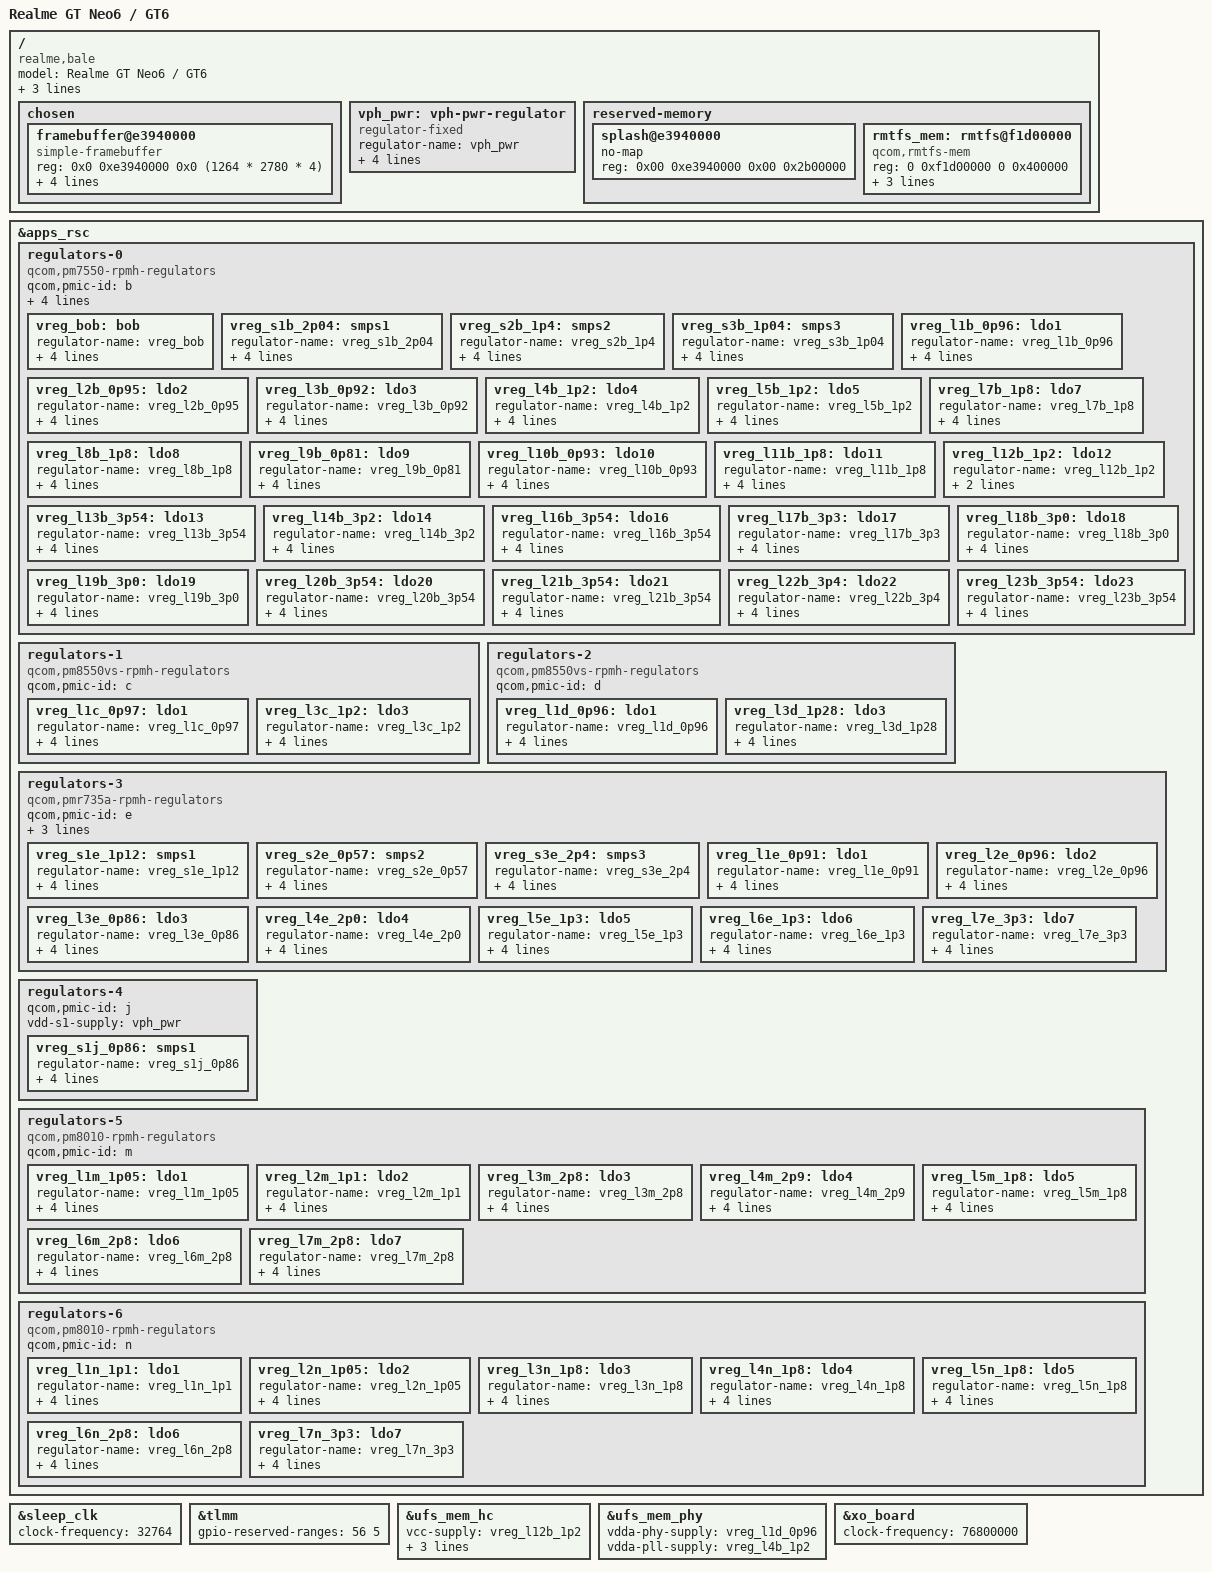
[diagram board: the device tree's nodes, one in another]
// SPDX-License-Identifier: BSD-3-Clause
/*
 * Copyright (c) 2025, Alexandr Zubtsov <internal.hellhound@mainlining.org>
 */

/dts-v1/;

#include <dt-bindings/regulator/qcom,rpmh-regulator.h>
#include "palawan.dtsi"
#include "pm8010.dtsi"
#include "pm7550.dtsi" /* PMXR2230 */
#include "pm7550ba.dtsi"
#define PMK8550VE_SID 3
#include "pm8550ve.dtsi"
#include "pm8550vs.dtsi"
#include "pmk8550.dtsi"
#include "pmr735a.dtsi"

/delete-node/ &rmtfs_mem;

/ {
	model = "Realme GT Neo6 / GT6";
	compatible = "realme,bale", "qcom,palawan";
	chassis-type = "handset";
	qcom,msm-id = <0x282 0x10000 0x266 0x10000>;
	qcom,board-id = <0x08 0x00>;

	chosen {
		#address-cells = <2>;
		#size-cells = <2>;
		ranges;
		framebuffer@e3940000 {
			compatible = "simple-framebuffer";
			reg = <0x0 0xe3940000 0x0 (1264 * 2780 * 4)>;
			width = <1264>;
			height = <2780>;
			stride = <(1264 * 4)>;
			format = "a8r8g8b8";
		};
	};

	vph_pwr: vph-pwr-regulator {
		compatible = "regulator-fixed";

		regulator-name = "vph_pwr";
		regulator-min-microvolt = <3700000>;
		regulator-max-microvolt = <3700000>;

		regulator-always-on;
		regulator-boot-on;
	};

	reserved-memory {
		splash@e3940000 {
			no-map;
			reg = <0x00 0xe3940000 0x00 0x2b00000>;
		};

		rmtfs_mem: rmtfs@f1d00000 {
			compatible = "qcom,rmtfs-mem";
			reg = <0 0xf1d00000 0 0x400000>;
			no-map;

			qcom,client-id = <1>;
			qcom,vmid = <QCOM_SCM_VMID_MSS_MSA>;
		};
	};
};

&apps_rsc {

	regulators-0 {
		compatible = "qcom,pm7550-rpmh-regulators";
		qcom,pmic-id = "b";

		vdd-bob-supply = <&vph_pwr>;
		vdd-s1-supply = <&vph_pwr>;
		vdd-s2-supply = <&vph_pwr>;
		vdd-s3-supply = <&vph_pwr>;

		vreg_bob: bob {
			regulator-name = "vreg_bob";
			regulator-min-microvolt = <3008000>;
			regulator-max-microvolt = <3960000>;
			regulator-initial-mode = <RPMH_REGULATOR_MODE_HPM>;
		};

		vreg_s1b_2p04: smps1 {
			regulator-name = "vreg_s1b_2p04";
			regulator-min-microvolt = <1856000>;
			regulator-max-microvolt = <2040000>;
			regulator-initial-mode = <RPMH_REGULATOR_MODE_HPM>;
		};

		vreg_s2b_1p4: smps2 {
			regulator-name = "vreg_s2b_1p4";
			regulator-min-microvolt = <1256000>;
			regulator-max-microvolt = <1408000>;
			regulator-initial-mode = <RPMH_REGULATOR_MODE_HPM>;
		};

		vreg_s3b_1p04: smps3 {
			regulator-name = "vreg_s3b_1p04";
			regulator-min-microvolt = <968000>;
			regulator-max-microvolt = <1040000>;
			regulator-initial-mode = <RPMH_REGULATOR_MODE_HPM>;
		};

		vreg_l1b_0p96: ldo1 {
			regulator-name = "vreg_l1b_0p96";
			regulator-min-microvolt = <880000>;
			regulator-max-microvolt = <960000>;
			regulator-initial-mode = <RPMH_REGULATOR_MODE_HPM>;
		};

		vreg_l2b_0p95: ldo2 {
			regulator-name = "vreg_l2b_0p95";
			regulator-min-microvolt = <880000>;
			regulator-max-microvolt = <952000>;
			regulator-initial-mode = <RPMH_REGULATOR_MODE_HPM>;
		};

		vreg_l3b_0p92: ldo3 {
			regulator-name = "vreg_l3b_0p92";
			regulator-min-microvolt = <880000>;
			regulator-max-microvolt = <920000>;
			regulator-initial-mode = <RPMH_REGULATOR_MODE_HPM>;
		};

		vreg_l4b_1p2: ldo4 {
			regulator-name = "vreg_l4b_1p2";
			regulator-min-microvolt = <1200000>;
			regulator-max-microvolt = <1200000>;
			regulator-initial-mode = <RPMH_REGULATOR_MODE_HPM>;
		};

		vreg_l5b_1p2: ldo5 {
			regulator-name = "vreg_l5b_1p2";
			regulator-min-microvolt = <1200000>;
			regulator-max-microvolt = <1200000>;
			regulator-initial-mode = <RPMH_REGULATOR_MODE_HPM>;
		};

		vreg_l7b_1p8: ldo7 {
			regulator-name = "vreg_l7b_1p8";
			regulator-min-microvolt = <1800000>;
			regulator-max-microvolt = <1800000>;
			regulator-initial-mode = <RPMH_REGULATOR_MODE_HPM>;
		};

		vreg_l8b_1p8: ldo8 {
			regulator-name = "vreg_l8b_1p8";
			regulator-min-microvolt = <1800000>;
			regulator-max-microvolt = <1800000>;
			regulator-initial-mode = <RPMH_REGULATOR_MODE_HPM>;
		};

		vreg_l9b_0p81: ldo9 {
			regulator-name = "vreg_l9b_0p81";
			regulator-min-microvolt = <756000>;
			regulator-max-microvolt = <816000>;
			regulator-initial-mode = <RPMH_REGULATOR_MODE_HPM>;
		};

		vreg_l10b_0p93: ldo10 {
			regulator-name = "vreg_l10b_0p93";
			regulator-min-microvolt = <868000>;
			regulator-max-microvolt = <932000>;
			regulator-initial-mode = <RPMH_REGULATOR_MODE_HPM>;
		};

		vreg_l11b_1p8: ldo11 {
			regulator-name = "vreg_l11b_1p8";
			regulator-min-microvolt = <1800000>;
			regulator-max-microvolt = <1800000>;
			regulator-initial-mode = <RPMH_REGULATOR_MODE_HPM>;
		};

		vreg_l12b_1p2: ldo12 {
			regulator-name = "vreg_l12b_1p2";
			regulator-initial-mode = <RPMH_REGULATOR_MODE_HPM>;
		};

		vreg_l13b_3p54: ldo13 {
			regulator-name = "vreg_l13b_3p54";
			regulator-min-microvolt = <1504000>;
			regulator-max-microvolt = <3544000>;
			regulator-initial-mode = <RPMH_REGULATOR_MODE_HPM>;
		};

		vreg_l14b_3p2: ldo14 {
			regulator-name = "vreg_l14b_3p2";
			regulator-min-microvolt = <3008000>;
			regulator-max-microvolt = <3200000>;
			regulator-initial-mode = <RPMH_REGULATOR_MODE_HPM>;
		};

		vreg_l16b_3p54: ldo16 {
			regulator-name = "vreg_l16b_3p54";
			regulator-min-microvolt = <2900000>;
			regulator-max-microvolt = <3544000>;
			regulator-initial-mode = <RPMH_REGULATOR_MODE_HPM>;
		};

		vreg_l17b_3p3: ldo17 {
			regulator-name = "vreg_l17b_3p3";
			regulator-min-microvolt = <2700000>;
			regulator-max-microvolt = <3300000>;
			regulator-initial-mode = <RPMH_REGULATOR_MODE_HPM>;
		};

		vreg_l18b_3p0: ldo18 {
			regulator-name = "vreg_l18b_3p0";
			regulator-min-microvolt = <2000000>;
			regulator-max-microvolt = <3000000>;
			regulator-initial-mode = <RPMH_REGULATOR_MODE_HPM>;
		};

		vreg_l19b_3p0: ldo19 {
			regulator-name = "vreg_l19b_3p0";
			regulator-min-microvolt = <2600000>;
			regulator-max-microvolt = <3000000>;
			regulator-initial-mode = <RPMH_REGULATOR_MODE_HPM>;
		};

		vreg_l20b_3p54: ldo20 {
			regulator-name = "vreg_l20b_3p54";
			regulator-min-microvolt = <1620000>;
			regulator-max-microvolt = <3544000>;
			regulator-initial-mode = <RPMH_REGULATOR_MODE_HPM>;
		};

		vreg_l21b_3p54: ldo21 {
			regulator-name = "vreg_l21b_3p54";
			regulator-min-microvolt = <1620000>;
			regulator-max-microvolt = <3544000>;
			regulator-initial-mode = <RPMH_REGULATOR_MODE_HPM>;
		};

		vreg_l22b_3p4: ldo22 {
			regulator-name = "vreg_l22b_3p4";
			regulator-min-microvolt = <2700000>;
			regulator-max-microvolt = <3400000>;
			regulator-initial-mode = <RPMH_REGULATOR_MODE_HPM>;
		};

		vreg_l23b_3p54: ldo23 {
			regulator-name = "vreg_l23b_3p54";
			regulator-min-microvolt = <1650000>;
			regulator-max-microvolt = <3544000>;
			regulator-initial-mode = <RPMH_REGULATOR_MODE_HPM>;
		};
	};

	regulators-1 {
		compatible = "qcom,pm8550vs-rpmh-regulators";
		qcom,pmic-id = "c";

		vreg_l1c_0p97: ldo1 {
			regulator-name = "vreg_l1c_0p97";
			regulator-min-microvolt = <904000>;
			regulator-max-microvolt = <972000>;
			regulator-initial-mode = <RPMH_REGULATOR_MODE_HPM>;
		};

		vreg_l3c_1p2: ldo3 {
			regulator-name = "vreg_l3c_1p2";
			regulator-min-microvolt = <1200000>;
			regulator-max-microvolt = <1200000>;
			regulator-initial-mode = <RPMH_REGULATOR_MODE_HPM>;
		};
	};

	regulators-2 { // PM8550V*
		compatible = "qcom,pm8550vs-rpmh-regulators";
		qcom,pmic-id = "d";

		vreg_l1d_0p96: ldo1 {
			regulator-name = "vreg_l1d_0p96";
			regulator-min-microvolt = <868000>;
			regulator-max-microvolt = <960000>;
			regulator-initial-mode = <RPMH_REGULATOR_MODE_HPM>;
		};

		vreg_l3d_1p28: ldo3 {
			regulator-name = "vreg_l3d_1p28";
			regulator-min-microvolt = <1160000>;
			regulator-max-microvolt = <1280000>;
			regulator-initial-mode = <RPMH_REGULATOR_MODE_HPM>;
		};
	};

	regulators-3 {
		compatible = "qcom,pmr735a-rpmh-regulators";
		qcom,pmic-id = "e";

		vdd-s1-supply = <&vph_pwr>;
		vdd-s2-supply = <&vph_pwr>;
		vdd-s3-supply = <&vph_pwr>;

		vreg_s1e_1p12: smps1 {
			regulator-name = "vreg_s1e_1p12";
			regulator-min-microvolt = <1012000>;
			regulator-max-microvolt = <1120000>;
			regulator-initial-mode = <RPMH_REGULATOR_MODE_HPM>;
		};

		vreg_s2e_0p57: smps2 {
			regulator-name = "vreg_s2e_0p57";
			regulator-min-microvolt = <300000>;
			regulator-max-microvolt = <572000>;
			regulator-initial-mode = <RPMH_REGULATOR_MODE_HPM>;
		};

		vreg_s3e_2p4: smps3 {
			regulator-name = "vreg_s3e_2p4";
			regulator-min-microvolt = <1600000>;
			regulator-max-microvolt = <2400000>;
			regulator-initial-mode = <RPMH_REGULATOR_MODE_HPM>;
		};

		vreg_l1e_0p91: ldo1 {
			regulator-name = "vreg_l1e_0p91";
			regulator-min-microvolt = <488000>;
			regulator-max-microvolt = <912000>;
			regulator-initial-mode = <RPMH_REGULATOR_MODE_HPM>;
		};

		vreg_l2e_0p96: ldo2 {
			regulator-name = "vreg_l2e_0p96";
			regulator-min-microvolt = <920000>;
			regulator-max-microvolt = <968000>;
			regulator-initial-mode = <RPMH_REGULATOR_MODE_HPM>;
		};

		vreg_l3e_0p86: ldo3 {
			regulator-name = "vreg_l3e_0p86";
			regulator-min-microvolt = <504000>;
			regulator-max-microvolt = <868000>;
			regulator-initial-mode = <RPMH_REGULATOR_MODE_HPM>;
		};

		vreg_l4e_2p0: ldo4 {
			regulator-name = "vreg_l4e_2p0";
			regulator-min-microvolt = <1620000>;
			regulator-max-microvolt = <2000000>;
			regulator-initial-mode = <RPMH_REGULATOR_MODE_HPM>;
		};

		vreg_l5e_1p3: ldo5 {
			regulator-name = "vreg_l5e_1p3";
			regulator-min-microvolt = <1100000>;
			regulator-max-microvolt = <1304000>;
			regulator-initial-mode = <RPMH_REGULATOR_MODE_HPM>;
		};

		vreg_l6e_1p3: ldo6 {
			regulator-name = "vreg_l6e_1p3";
			regulator-min-microvolt = <1080000>;
			regulator-max-microvolt = <1304000>;
			regulator-initial-mode = <RPMH_REGULATOR_MODE_HPM>;
		};

		vreg_l7e_3p3: ldo7 {
			regulator-name = "vreg_l7e_3p3";
			regulator-min-microvolt = <1620000>;
			regulator-max-microvolt = <3300000>;
			regulator-initial-mode = <RPMH_REGULATOR_MODE_HPM>;
		};
	};

	regulators-4 {
		qcom,pmic-id = "j";

		vdd-s1-supply = <&vph_pwr>;

		vreg_s1j_0p86: smps1 {
			regulator-name = "vreg_s1j_0p86";
			regulator-min-microvolt = <504000>;
			regulator-max-microvolt = <868000>;
			regulator-initial-mode = <RPMH_REGULATOR_MODE_HPM>;
		};
	};

	regulators-5 {
		compatible = "qcom,pm8010-rpmh-regulators";
		qcom,pmic-id = "m";

		vreg_l1m_1p05: ldo1 {
			regulator-name = "vreg_l1m_1p05";
			regulator-min-microvolt = <1052000>;
			regulator-max-microvolt = <1052000>;
			regulator-initial-mode = <RPMH_REGULATOR_MODE_HPM>;
		};

		vreg_l2m_1p1: ldo2 {
			regulator-name = "vreg_l2m_1p1";
			regulator-min-microvolt = <1100000>;
			regulator-max-microvolt = <1100000>;
			regulator-initial-mode = <RPMH_REGULATOR_MODE_HPM>;
		};

		vreg_l3m_2p8: ldo3 {
			regulator-name = "vreg_l3m_2p8";
			regulator-min-microvolt = <2800000>;
			regulator-max-microvolt = <2800000>;
			regulator-initial-mode = <RPMH_REGULATOR_MODE_HPM>;
		};

		vreg_l4m_2p9: ldo4 {
			regulator-name = "vreg_l4m_2p9";
			regulator-min-microvolt = <2700000>;
			regulator-max-microvolt = <2900000>;
			regulator-initial-mode = <RPMH_REGULATOR_MODE_HPM>;
		};

		vreg_l5m_1p8: ldo5 {
			regulator-name = "vreg_l5m_1p8";
			regulator-min-microvolt = <1800000>;
			regulator-max-microvolt = <1800000>;
			regulator-initial-mode = <RPMH_REGULATOR_MODE_HPM>;
		};

		vreg_l6m_2p8: ldo6 {
			regulator-name = "vreg_l6m_2p8";
			regulator-min-microvolt = <2800000>;
			regulator-max-microvolt = <2800000>;
			regulator-initial-mode = <RPMH_REGULATOR_MODE_HPM>;
		};

		vreg_l7m_2p8: ldo7 {
			regulator-name = "vreg_l7m_2p8";
			regulator-min-microvolt = <2800000>;
			regulator-max-microvolt = <2800000>;
			regulator-initial-mode = <RPMH_REGULATOR_MODE_HPM>;
		};
	};

	regulators-6 {
		compatible = "qcom,pm8010-rpmh-regulators";
		qcom,pmic-id = "n";

		vreg_l1n_1p1: ldo1 {
			regulator-name = "vreg_l1n_1p1";
			regulator-min-microvolt = <1104000>;
			regulator-max-microvolt = <1104000>;
			regulator-initial-mode = <RPMH_REGULATOR_MODE_HPM>;
		};

		vreg_l2n_1p05: ldo2 {
			regulator-name = "vreg_l2n_1p05";
			regulator-min-microvolt = <1056000>;
			regulator-max-microvolt = <1056000>;
			regulator-initial-mode = <RPMH_REGULATOR_MODE_HPM>;
		};

		vreg_l3n_1p8: ldo3 {
			regulator-name = "vreg_l3n_1p8";
			regulator-min-microvolt = <1800000>;
			regulator-max-microvolt = <1800000>;
			regulator-initial-mode = <RPMH_REGULATOR_MODE_HPM>;
		};

		vreg_l4n_1p8: ldo4 {
			regulator-name = "vreg_l4n_1p8";
			regulator-min-microvolt = <1800000>;
			regulator-max-microvolt = <1800000>;
			regulator-initial-mode = <RPMH_REGULATOR_MODE_HPM>;
		};

		vreg_l5n_1p8: ldo5 {
			regulator-name = "vreg_l5n_1p8";
			regulator-min-microvolt = <1800000>;
			regulator-max-microvolt = <1800000>;
			regulator-initial-mode = <RPMH_REGULATOR_MODE_HPM>;
		};

		vreg_l6n_2p8: ldo6 {
			regulator-name = "vreg_l6n_2p8";
			regulator-min-microvolt = <2800000>;
			regulator-max-microvolt = <2800000>;
			regulator-initial-mode = <RPMH_REGULATOR_MODE_HPM>;
		};

		vreg_l7n_3p3: ldo7 {
			regulator-name = "vreg_l7n_3p3";
			regulator-min-microvolt = <3304000>;
			regulator-max-microvolt = <3304000>;
			regulator-initial-mode = <RPMH_REGULATOR_MODE_HPM>;
		};
	};
};

&sleep_clk {
	clock-frequency = <32764>;
};

&tlmm {
  gpio-reserved-ranges = <56 5>;
};

&ufs_mem_hc {
	vcc-supply = <&vreg_l12b_1p2>;
	vcc-max-microamp = <1200000>;
	vccq-supply = <&vreg_l3d_1p28>;
	vccq-max-microamp = <1200000>;
	status = "okay";
};

&ufs_mem_phy {
	vdda-phy-supply = <&vreg_l1d_0p96>;
	vdda-pll-supply = <&vreg_l4b_1p2>;
	status = "okay";
};

&xo_board {
	clock-frequency = <76800000>;
};
